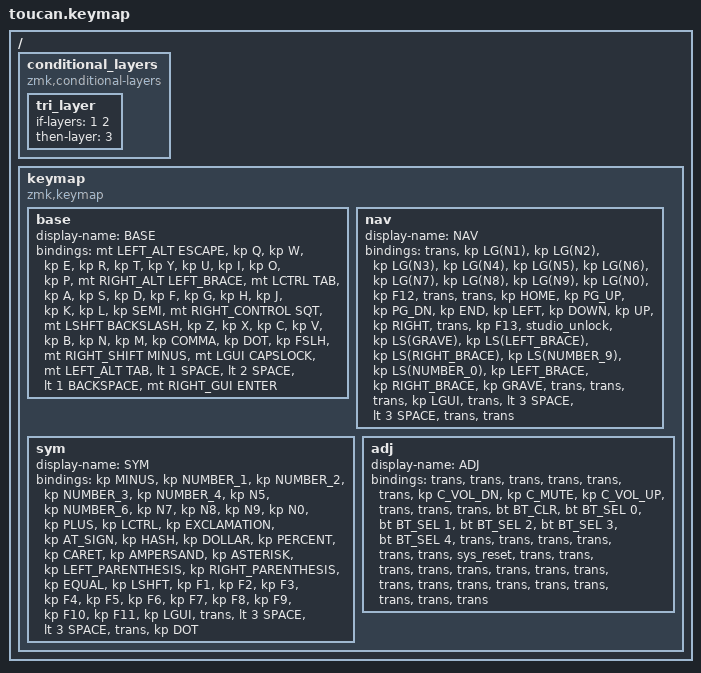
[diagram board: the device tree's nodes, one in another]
#include <behaviors.dtsi>
#include <dt-bindings/zmk/bt.h>
#include <dt-bindings/zmk/keys.h>

#define BASE 0
#define NAV  1
#define SYM  2
#define ADJ  3

/ {
    conditional_layers {
        compatible = "zmk,conditional-layers";

        tri_layer {
            if-layers = <1 2>;
            then-layer = <3>;
        };
    };

    keymap {
        compatible = "zmk,keymap";

        base {
            display-name = "BASE";
            bindings = <
&mt LEFT_ALT ESCAPE  &kp Q  &kp W  &kp E  &kp R  &kp T  &kp Y  &kp U  &kp I  &kp O  &kp P  &mt RIGHT_ALT LEFT_BRACE  &mt LCTRL TAB  &kp A  &kp S  &kp D  &kp F  &kp G  &kp H  &kp J  &kp K  &kp L  &kp SEMI  &mt RIGHT_CONTROL SQT  &mt LSHFT BACKSLASH  &kp Z  &kp X  &kp C  &kp V  &kp B  &kp N  &kp M  &kp COMMA  &kp DOT  &kp FSLH  &mt RIGHT_SHIFT MINUS  &mt LGUI CAPSLOCK  &mt LEFT_ALT TAB  &lt 1 SPACE  &lt 2 SPACE  &lt 1 BACKSPACE  &mt RIGHT_GUI ENTER
            >;
        };

        nav {
            display-name = "NAV";
            bindings = <
&trans  &kp LG(N1)  &kp LG(N2)  &kp LG(N3)  &kp LG(N4)  &kp LG(N5)  &kp LG(N6)  &kp LG(N7)  &kp LG(N8)  &kp LG(N9)  &kp LG(N0)  &kp F12  &trans  &trans  &kp HOME  &kp PG_UP  &kp PG_DN  &kp END  &kp LEFT  &kp DOWN  &kp UP  &kp RIGHT  &trans  &kp F13  &studio_unlock  &kp LS(GRAVE)  &kp LS(LEFT_BRACE)  &kp LS(RIGHT_BRACE)  &kp LS(NUMBER_9)  &kp LS(NUMBER_0)  &kp LEFT_BRACE  &kp RIGHT_BRACE  &kp GRAVE  &trans  &trans  &trans  &kp LGUI  &trans  &lt 3 SPACE  &lt 3 SPACE  &trans  &trans
            >;
        };

        sym {
            display-name = "SYM";
            bindings = <
&kp MINUS  &kp NUMBER_1  &kp NUMBER_2  &kp NUMBER_3  &kp NUMBER_4  &kp N5  &kp NUMBER_6  &kp N7  &kp N8  &kp N9  &kp N0  &kp PLUS  &kp LCTRL  &kp EXCLAMATION  &kp AT_SIGN  &kp HASH  &kp DOLLAR  &kp PERCENT  &kp CARET  &kp AMPERSAND  &kp ASTERISK  &kp LEFT_PARENTHESIS  &kp RIGHT_PARENTHESIS  &kp EQUAL  &kp LSHFT  &kp F1  &kp F2  &kp F3  &kp F4  &kp F5  &kp F6  &kp F7  &kp F8  &kp F9  &kp F10  &kp F11  &kp LGUI  &trans  &lt 3 SPACE  &lt 3 SPACE  &trans  &kp DOT
            >;
        };

        adj {
            display-name = "ADJ";
            bindings = <
&trans  &trans  &trans  &trans  &trans  &trans  &kp C_VOL_DN  &kp C_MUTE  &kp C_VOL_UP  &trans  &trans  &trans  &bt BT_CLR  &bt BT_SEL 0  &bt BT_SEL 1  &bt BT_SEL 2  &bt BT_SEL 3  &bt BT_SEL 4  &trans  &trans  &trans  &trans  &trans  &trans  &sys_reset  &trans  &trans  &trans  &trans  &trans  &trans  &trans  &trans  &trans  &trans  &trans  &trans  &trans  &trans  &trans  &trans  &trans
            >;
        };
    };
};
